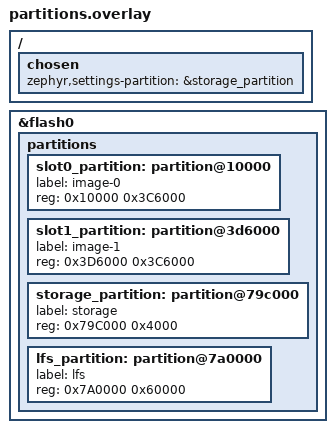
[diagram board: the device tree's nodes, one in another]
/*
 * Flash partition layout — SHARED by the app image and MCUboot.
 *
 * This file is fed to BOTH images (app via EXTRA_DTC_OVERLAY_FILE, MCUboot via
 * mcuboot_EXTRA_DTC_OVERLAY_FILE in sysbuild/CMakeLists.txt) so their flash maps
 * are identical — otherwise MCUboot looks for the OTA image at a different
 * address than the app writes it to and OTA silently reverts. Keep it free of
 * app-only nodes (drivers, chosen mounts) so MCUboot can consume it too.
 *
 * slot0 starts at 0x10000 (right after the 64KB MCUboot region), matching the
 * Arduino/ESP-IDF app offset so Mesh America's app-only "flash-update" works.
 * sys_partition (0x10000, virtual-eFuse scratch — unused, virtual eFuse off) is
 * reclaimed. Each slot is grown 0x8000 vs the old 0x20000 layout so slot0 == slot1
 * and slot1 ends exactly on the unchanged storage/lfs offsets — the reflash keeps
 * identity/prefs/contacts/BLE-bonds byte-identical.
 *
 * 8MB layout: MCUboot 0x0..0x10000, slot0/slot1 0x3C6000 each, storage+lfs at top.
 */
/delete-node/ &sys_partition;
/delete-node/ &slot0_lpcore_partition;
/delete-node/ &slot1_lpcore_partition;
/delete-node/ &storage_partition;
/delete-node/ &scratch_partition;
/delete-node/ &coredump_partition;
/delete-node/ &slot0_partition;
/delete-node/ &slot1_partition;

/ {
	chosen {
		zephyr,settings-partition = &storage_partition;
	};
};

&flash0 {
	partitions {
		/* App slots — equal size (swap-mode compatible), slot0 at 0x10000. */
		slot0_partition: partition@10000 {
			label = "image-0";
			reg = <0x10000 0x3C6000>;
		};
		slot1_partition: partition@3d6000 {
			label = "image-1";
			reg = <0x3D6000 0x3C6000>;
		};
		/* BLE bond store — 16KB NVS, isolated from /lfs (see esp32_common.conf).
		 * Offset unchanged so existing bonds survive the reflash. */
		storage_partition: partition@79c000 {
			label = "storage";
			reg = <0x79C000 0x4000>;
		};
		/* LittleFS 384KB for DataStore (identity, prefs, contacts).
		 * Offset unchanged so existing identity/prefs/contacts survive. */
		lfs_partition: partition@7a0000 {
			label = "lfs";
			reg = <0x7A0000 0x60000>;
		};
	};
};
